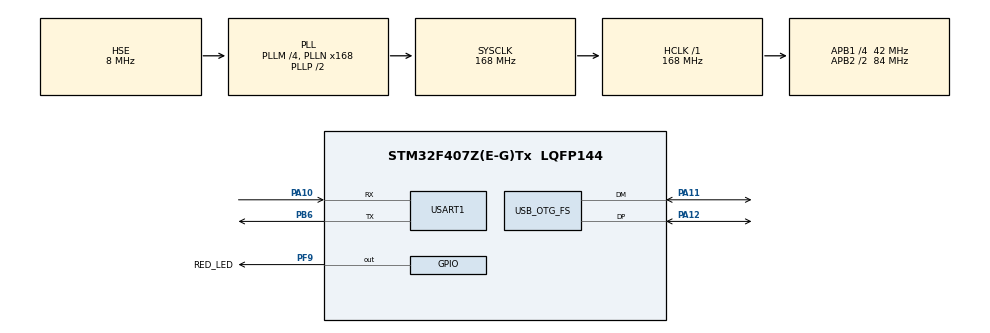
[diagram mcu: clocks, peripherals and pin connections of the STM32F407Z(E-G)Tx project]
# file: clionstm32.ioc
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Mcu.Family=STM32F4
Mcu.Name=STM32F407Z(E-G)Tx
Mcu.Package=LQFP144
NVIC.OTG_FS_IRQn=true\:15\:0\:true\:false\:true\:false\:true\:true\:true
NVIC.PriorityGroup=NVIC_PRIORITYGROUP_4
NVIC.TIM4_IRQn=true\:10\:0\:true\:false\:true\:false\:false\:true\:true
NVIC.TimeBase=TIM4_IRQn
NVIC.TimeBaseIP=TIM4
PA10.Mode=Asynchronous
PA10.Signal=USART1_RX
PA11.Mode=Host_Only
PA11.Signal=USB_OTG_FS_DM
PA12.Mode=Host_Only
PA12.Signal=USB_OTG_FS_DP
PA13.Mode=Serial_Wire
PA13.Signal=SYS_JTMS-SWDIO
PA14.Mode=Serial_Wire
PA14.Signal=SYS_JTCK-SWCLK
PB6.Mode=Asynchronous
PB6.Signal=USART1_TX
PF9.GPIO_Label=RED_LED
PF9.Signal=GPIO_Output
PH0-OSC_IN.Mode=HSE-External-Oscillator
PH0-OSC_IN.Signal=RCC_OSC_IN
PH1-OSC_OUT.Mode=HSE-External-Oscillator
PH1-OSC_OUT.Signal=RCC_OSC_OUT
ProjectManager.HeapSize=0x200
ProjectManager.StackSize=0x400
ProjectManager.TargetToolchain=MDK-ARM V5.32
RCC.48MHZClocksFreq_Value=48000000
RCC.AHBFreq_Value=168000000
RCC.APB1CLKDivider=RCC_HCLK_DIV4
RCC.APB1Freq_Value=42000000
RCC.APB1TimFreq_Value=84000000
RCC.APB2CLKDivider=RCC_HCLK_DIV2
RCC.APB2Freq_Value=84000000
RCC.APB2TimFreq_Value=168000000
RCC.CortexFreq_Value=168000000
RCC.HCLKFreq_Value=168000000
RCC.HSE_VALUE=8000000
RCC.HSI_VALUE=16000000
RCC.LSE_VALUE=32768
RCC.PLLM=4
RCC.PLLN=168
RCC.PLLQ=7
RCC.SYSCLKFreq_VALUE=168000000
RCC.SYSCLKSource=RCC_SYSCLKSOURCE_PLLCLK
RCC.VCOOutputFreq_Value=336000000
STMicroelectronics.X-CUBE-AZRTOS-F4.1.1.0.FileXCcFileOoSystemJjFileXJjCore=true
STMicroelectronics.X-CUBE-AZRTOS-F4.1.1.0.InterfacesCcFileOoSystemJjFileXOoCustomOointerface=true
STMicroelectronics.X-CUBE-AZRTOS-F4.1.1.0.LevelXCcFileOoSystemJjLevelXJjNOROoFlashOoSupport=true
STMicroelectronics.X-CUBE-AZRTOS-F4.1.1.0.ThreadXCcRTOSJjThreadXJjCore=true
STMicroelectronics.X-CUBE-AZRTOS-F4.1.1.0.ThreadXCcRTOSJjThreadXJjLowOoPowerOosupport=true
STMicroelectronics.X-CUBE-AZRTOS-F4.1.1.0.ThreadXCcRTOSJjThreadXJjPerformanceInfo=true
STMicroelectronics.X-CUBE-AZRTOS-F4.1.1.0.ThreadXCcRTOSJjThreadXJjTraceXOosupport=true
STMicroelectronics.X-CUBE-AZRTOS-F4.1.1.0.USBXCcUSBJjUSBXJjCoreSystem=true
STMicroelectronics.X-CUBE-AZRTOS-F4.1.1.0.USBXCcUSBJjUSBXJjUXOoHostOoClassOoHIDOoCore=true
STMicroelectronics.X-CUBE-AZRTOS-F4.1.1.0.USBXCcUSBJjUSBXJjUXOoHostOoClassOoHIDOoKeyboard=true
STMicroelectronics.X-CUBE-AZRTOS-F4.1.1.0.USBXCcUSBJjUSBXJjUXOoHostOoClassOoHIDOoMouse=true
STMicroelectronics.X-CUBE-AZRTOS-F4.1.1.0.USBXCcUSBJjUSBXJjUXOoHostOoClassOoHIDOoRCU=true
STMicroelectronics.X-CUBE-AZRTOS-F4.1.1.0.USBXCcUSBJjUSBXJjUXOoHostOoClassOoSTORAGE=true
STMicroelectronics.X-CUBE-AZRTOS-F4.1.1.0.USBXCcUSBJjUSBXJjUXOoHostOoControllers=true
STMicroelectronics.X-CUBE-AZRTOS-F4.1.1.0.USBXCcUSBJjUSBXJjUXOoHostOoCoreStack=true
STMicroelectronics.X-CUBE-AZRTOS-F4.1.1.0_IsAnAzureRtosMw=true
USART1.VirtualMode=VM_ASYNC
USB_OTG_FS.VirtualMode=Host_Only
USB_OTG_FS.phy_itface=HCD_PHY_EMBEDDED
VP_STMicroelectronics.X-CUBE-AZRTOS-F4_VS_FileOoSystemJjFileX_6.1.10_1.1.0.Mode=FileOoSystemJjFileX
VP_STMicroelectronics.X-CUBE-AZRTOS-F4_VS_FileOoSystemJjInterfaces_2.1.0_1.1.0.Mode=FileOoSystemJjInterfaces
VP_STMicroelectronics.X-CUBE-AZRTOS-F4_VS_FileOoSystemJjLevelX_6.1.10_1.1.0.Mode=FileOoSystemJjLevelX
VP_STMicroelectronics.X-CUBE-AZRTOS-F4_VS_RTOSJjThreadX_6.1.10_1.1.0.Mode=RTOSJjThreadX
VP_STMicroelectronics.X-CUBE-AZRTOS-F4_VS_USBJjUSBX_6.1.10_1.1.0.Mode=USBJjUSBX
VP_SYS_VS_tim4.Mode=TIM4
board=custom

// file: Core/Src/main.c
/* USER CODE BEGIN Header */
/**
  ******************************************************************************
  * @file           : main.c
  * @brief          : Main program body
  ******************************************************************************
  * @attention
  *
  * Copyright (c) 2026 STMicroelectronics.
  * All rights reserved.
  *
  * This software is licensed under terms that can be found in the LICENSE file
  * in the root directory of this software component.
  * If no LICENSE file comes with this software, it is provided AS-IS.
  *
  ******************************************************************************
  */
/* USER CODE END Header */
#include "app_threadx.h"
#include "main.h"

UART_HandleTypeDef huart1;

HCD_HandleTypeDef hhcd_USB_OTG_FS;

void SystemClock_Config(void);
static void MX_GPIO_Init(void);
static void MX_USART1_UART_Init(void);
static void MX_USB_OTG_FS_HCD_Init(void);

int main(void)
{

  /* MCU Configuration--------------------------------------------------------*/

  /* Reset of all peripherals, Initializes the Flash interface and the Systick. */
  HAL_Init();

  /* Configure the system clock */
  SystemClock_Config();

  /* Initialize all configured peripherals */
  MX_GPIO_Init();
  MX_USART1_UART_Init();
  MX_USB_OTG_FS_HCD_Init();
  /* USER CODE BEGIN 2 */
  {
    /* Earliest possible diagnostic: confirm the firmware is running */
    const char boot_msg[] = "\r\n\r\n=== STM32 BOOT OK ===\r\n";
    HAL_UART_Transmit(&huart1, (uint8_t *)boot_msg, sizeof(boot_msg) - 1, 1000);
  }
  /* USER CODE END 2 */

  MX_ThreadX_Init();

  /* We should never get here as control is now taken by the scheduler */

  /* Infinite loop */
  while (1)
  {

  }
}

void SystemClock_Config(void)
{
  RCC_OscInitTypeDef RCC_OscInitStruct = {0};
  RCC_ClkInitTypeDef RCC_ClkInitStruct = {0};

  /** Configure the main internal regulator output voltage
  */
  __HAL_RCC_PWR_CLK_ENABLE();
  __HAL_PWR_VOLTAGESCALING_CONFIG(PWR_REGULATOR_VOLTAGE_SCALE1);

  /** Initializes the RCC Oscillators according to the specified parameters
  * in the RCC_OscInitTypeDef structure.
  */
  RCC_OscInitStruct.OscillatorType = RCC_OSCILLATORTYPE_HSE;
  RCC_OscInitStruct.HSEState = RCC_HSE_ON;
  RCC_OscInitStruct.PLL.PLLState = RCC_PLL_ON;
  RCC_OscInitStruct.PLL.PLLSource = RCC_PLLSOURCE_HSE;
  RCC_OscInitStruct.PLL.PLLM = 4;
  RCC_OscInitStruct.PLL.PLLN = 168;
  RCC_OscInitStruct.PLL.PLLP = RCC_PLLP_DIV2;
  RCC_OscInitStruct.PLL.PLLQ = 7;
  if (HAL_RCC_OscConfig(&RCC_OscInitStruct) != HAL_OK)
  {
    Error_Handler();
  }

  /** Initializes the CPU, AHB and APB buses clocks
  */
  RCC_ClkInitStruct.ClockType = RCC_CLOCKTYPE_HCLK|RCC_CLOCKTYPE_SYSCLK
                              |RCC_CLOCKTYPE_PCLK1|RCC_CLOCKTYPE_PCLK2;
  RCC_ClkInitStruct.SYSCLKSource = RCC_SYSCLKSOURCE_PLLCLK;
  RCC_ClkInitStruct.AHBCLKDivider = RCC_SYSCLK_DIV1;
  RCC_ClkInitStruct.APB1CLKDivider = RCC_HCLK_DIV4;
  RCC_ClkInitStruct.APB2CLKDivider = RCC_HCLK_DIV2;

  if (HAL_RCC_ClockConfig(&RCC_ClkInitStruct, FLASH_LATENCY_5) != HAL_OK)
  {
    Error_Handler();
  }
}

static void MX_USART1_UART_Init(void)
{

  huart1.Instance = USART1;
  huart1.Init.BaudRate = 115200;
  huart1.Init.WordLength = UART_WORDLENGTH_8B;
  huart1.Init.StopBits = UART_STOPBITS_1;
  huart1.Init.Parity = UART_PARITY_NONE;
  huart1.Init.Mode = UART_MODE_TX_RX;
  huart1.Init.HwFlowCtl = UART_HWCONTROL_NONE;
  huart1.Init.OverSampling = UART_OVERSAMPLING_16;
  if (HAL_UART_Init(&huart1) != HAL_OK)
  {
    Error_Handler();
  }

}

static void MX_USB_OTG_FS_HCD_Init(void)
{

  hhcd_USB_OTG_FS.Instance = USB_OTG_FS;
  hhcd_USB_OTG_FS.Init.Host_channels = 8;
  hhcd_USB_OTG_FS.Init.speed = HCD_SPEED_FULL;
  hhcd_USB_OTG_FS.Init.dma_enable = DISABLE;
  hhcd_USB_OTG_FS.Init.phy_itface = HCD_PHY_EMBEDDED;
  hhcd_USB_OTG_FS.Init.Sof_enable = ENABLE;
  hhcd_USB_OTG_FS.Init.vbus_sensing_enable = DISABLE;
  if (HAL_HCD_Init(&hhcd_USB_OTG_FS) != HAL_OK)
  {
    Error_Handler();
  }

}

static void MX_GPIO_Init(void)
{
  GPIO_InitTypeDef GPIO_InitStruct = {0};

  /* GPIO Ports Clock Enable */
  __HAL_RCC_GPIOF_CLK_ENABLE();
  __HAL_RCC_GPIOH_CLK_ENABLE();
  __HAL_RCC_GPIOA_CLK_ENABLE();
  __HAL_RCC_GPIOB_CLK_ENABLE();

  /*Configure GPIO pin Output Level */
  HAL_GPIO_WritePin(RED_LED_GPIO_Port, RED_LED_Pin, GPIO_PIN_RESET);

  /*Configure GPIO pin : RED_LED_Pin */
  GPIO_InitStruct.Pin = RED_LED_Pin;
  GPIO_InitStruct.Mode = GPIO_MODE_OUTPUT_PP;
  GPIO_InitStruct.Pull = GPIO_NOPULL;
  GPIO_InitStruct.Speed = GPIO_SPEED_FREQ_LOW;
  HAL_GPIO_Init(RED_LED_GPIO_Port, &GPIO_InitStruct);

  /* USER CODE BEGIN MX_GPIO_Init_2 */
  /* 正点原子探索者 USB Host 电源使能 (PA15, 高电平有效) */
  HAL_GPIO_WritePin(USB_HOST_PWR_EN_GPIO_Port, USB_HOST_PWR_EN_Pin, GPIO_PIN_SET);

  /* Configure the board-level USB host power switch. */
  GPIO_InitStruct.Pin = USB_HOST_PWR_EN_Pin;
  GPIO_InitStruct.Mode = GPIO_MODE_OUTPUT_PP;
  GPIO_InitStruct.Pull = GPIO_NOPULL;
  GPIO_InitStruct.Speed = GPIO_SPEED_FREQ_LOW;
  HAL_GPIO_Init(USB_HOST_PWR_EN_GPIO_Port, &GPIO_InitStruct);

  /* USER CODE END MX_GPIO_Init_2 */
}

void HAL_TIM_PeriodElapsedCallback(TIM_HandleTypeDef *htim)
{
  if (htim->Instance == TIM4)
  {
    HAL_IncTick();
  }
}

void Error_Handler(void)
{
  __disable_irq();
  while (1)
  {
  }
}
